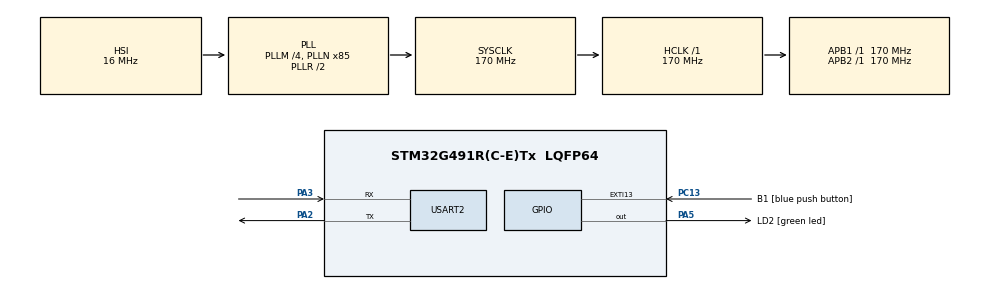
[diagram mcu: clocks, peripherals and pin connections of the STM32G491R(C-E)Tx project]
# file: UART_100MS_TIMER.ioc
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Mcu.Family=STM32G4
Mcu.Name=STM32G491R(C-E)Tx
Mcu.Package=LQFP64
NVIC.EXTI15_10_IRQn=true\:0\:0\:false\:false\:true\:true\:true\:true
NVIC.PriorityGroup=NVIC_PRIORITYGROUP_4
NVIC.TIM6_DAC_IRQn=true\:0\:0\:false\:false\:true\:true\:true\:true
NVIC.USART2_IRQn=true\:0\:0\:false\:false\:true\:true\:true\:true
PA13.GPIO_Label=T_SWDIO
PA13.Signal=SYS_JTMS-SWDIO
PA14.GPIO_Label=T_SWCLK
PA14.Signal=SYS_JTCK-SWCLK
PA2.Mode=Asynchronous
PA2.Signal=USART2_TX
PA3.Mode=Asynchronous
PA3.Signal=USART2_RX
PA5.GPIO_Label=LD2 [green led]
PA5.Signal=GPIO_Output
PB3.GPIO_Label=T_SWO
PB3.Signal=SYS_JTDO-SWO
PC13.GPIO_Label=B1 [blue push button]
PC13.Signal=GPXTI13
PC14-OSC32_IN.GPIO_Label=RCC_OSC32_IN
PC14-OSC32_IN.Signal=RCC_OSC32_IN
PC15-OSC32_OUT.GPIO_Label=RCC_OSC32_OUT
PC15-OSC32_OUT.Signal=RCC_OSC32_OUT
PF0-OSC_IN.GPIO_Label=RCC_OSC_IN
PF0-OSC_IN.Mode=HSE-External-Oscillator
PF0-OSC_IN.Signal=RCC_OSC_IN
PF1-OSC_OUT.GPIO_Label=RCC_OSC_OUT
PF1-OSC_OUT.Mode=HSE-External-Oscillator
PF1-OSC_OUT.Signal=RCC_OSC_OUT
ProjectManager.HeapSize=0x200
ProjectManager.StackSize=0x400
ProjectManager.TargetToolchain=STM32CubeIDE
RCC.ADC12Freq_Value=170000000
RCC.ADC345Freq_Value=170000000
RCC.AHBFreq_Value=170000000
RCC.APB1Freq_Value=170000000
RCC.APB1TimFreq_Value=170000000
RCC.APB2Freq_Value=170000000
RCC.APB2TimFreq_Value=170000000
RCC.CortexFreq_Value=170000000
RCC.EXTERNAL_CLOCK_VALUE=12288000
RCC.HCLKFreq_Value=170000000
RCC.HSE_VALUE=24000000
RCC.HSI48_VALUE=48000000
RCC.HSI_VALUE=16000000
RCC.LSE_VALUE=32768
RCC.PLLM=RCC_PLLM_DIV4
RCC.PLLN=85
RCC.RTCClockSelection=RCC_RTCCLKSOURCE_LSE
RCC.SYSCLKFreq_VALUE=170000000
RCC.SYSCLKSource=RCC_SYSCLKSOURCE_PLLCLK
RCC.USBFreq_Value=48000000
RCC.VCOOutputFreq_Value=340000000
TIM6.PeriodNoDither=1000-1
TIM6.Prescaler=17000-1
USART2.VirtualMode-Asynchronous=VM_ASYNC
VP_SYS_VS_DBSignals.Mode=DisableDeadBatterySignals
VP_TIM6_VS_ClockSourceINT.Mode=Enable_Timer
board=NUCLEO-G491RE

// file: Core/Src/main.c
/* USER CODE BEGIN Header */
/**
  ******************************************************************************
  * @file           : main.c
  * @brief          : Main program body
  ******************************************************************************
  */
/* USER CODE END Header */

#include "main.h"

TIM_HandleTypeDef htim6;
UART_HandleTypeDef huart2;

/* USER CODE BEGIN PV */
volatile uint8_t uart_send_flag = 0;
uint8_t TX_Buffer[] = "Hello World\r\n";
/* USER CODE END PV */

void SystemClock_Config(void);
static void MX_GPIO_Init(void);
static void MX_TIM6_Init(void);
static void MX_USART2_UART_Init(void);

int main(void)
{
  HAL_Init();
  SystemClock_Config();

  MX_GPIO_Init();
  MX_TIM6_Init();
  MX_USART2_UART_Init();

  /* Start TIM6 interrupt (100 ms hardware timer) */
  HAL_TIM_Base_Start_IT(&htim6);

  while (1)
  {
    /* Handle UART transmission outside interrupt */
    if (uart_send_flag)
    {
      uart_send_flag = 0;

      HAL_UART_Transmit(&huart2,
                        TX_Buffer,
                        sizeof(TX_Buffer) - 1,
                        HAL_MAX_DELAY);
    }
  }
}

/* ================= TIMER 6 INIT ================= */

static void MX_TIM6_Init(void)
{
  TIM_MasterConfigTypeDef sMasterConfig = {0};

  htim6.Instance = TIM6;
  htim6.Init.Prescaler = 17000 - 1;   // 170 MHz / 17000 = 10 kHz
  htim6.Init.CounterMode = TIM_COUNTERMODE_UP;
  htim6.Init.Period = 1000 - 1;       // 1000 ticks = 100 ms
  htim6.Init.AutoReloadPreload = TIM_AUTORELOAD_PRELOAD_DISABLE;

  if (HAL_TIM_Base_Init(&htim6) != HAL_OK)
  {
    Error_Handler();
  }

  sMasterConfig.MasterOutputTrigger = TIM_TRGO_RESET;
  sMasterConfig.MasterSlaveMode = TIM_MASTERSLAVEMODE_DISABLE;

  if (HAL_TIMEx_MasterConfigSynchronization(&htim6, &sMasterConfig) != HAL_OK)
  {
    Error_Handler();
  }
}

/* ================= UART INIT ================= */

static void MX_USART2_UART_Init(void)
{
  huart2.Instance = USART2;
  huart2.Init.BaudRate = 115200;
  huart2.Init.WordLength = UART_WORDLENGTH_8B;
  huart2.Init.StopBits = UART_STOPBITS_1;
  huart2.Init.Parity = UART_PARITY_NONE;
  huart2.Init.Mode = UART_MODE_TX_RX;
  huart2.Init.HwFlowCtl = UART_HWCONTROL_NONE;
  huart2.Init.OverSampling = UART_OVERSAMPLING_16;
  huart2.Init.OneBitSampling = UART_ONE_BIT_SAMPLE_DISABLE;
  huart2.Init.ClockPrescaler = UART_PRESCALER_DIV1;
  huart2.AdvancedInit.AdvFeatureInit = UART_ADVFEATURE_NO_INIT;

  if (HAL_UART_Init(&huart2) != HAL_OK)
  {
    Error_Handler();
  }
}

/* ================= GPIO INIT ================= */

static void MX_GPIO_Init(void)
{
  GPIO_InitTypeDef GPIO_InitStruct = {0};

  __HAL_RCC_GPIOC_CLK_ENABLE();
  __HAL_RCC_GPIOF_CLK_ENABLE();
  __HAL_RCC_GPIOA_CLK_ENABLE();
  __HAL_RCC_GPIOB_CLK_ENABLE();

  HAL_GPIO_WritePin(LD2_GPIO_Port, LD2_Pin, GPIO_PIN_RESET);

  GPIO_InitStruct.Pin = LD2_Pin;
  GPIO_InitStruct.Mode = GPIO_MODE_OUTPUT_PP;
  GPIO_InitStruct.Pull = GPIO_NOPULL;
  GPIO_InitStruct.Speed = GPIO_SPEED_FREQ_LOW;
  HAL_GPIO_Init(LD2_GPIO_Port, &GPIO_InitStruct);
}

/* ================= TIMER CALLBACK ================= */

void HAL_TIM_PeriodElapsedCallback(TIM_HandleTypeDef *htim)
{
  if (htim->Instance == TIM6)
  {
    uart_send_flag = 1;   // Set flag only (fast, safe ISR)
  }
}

/* ================= CLOCK CONFIG ================= */

void SystemClock_Config(void)
{
  RCC_OscInitTypeDef RCC_OscInitStruct = {0};
  RCC_ClkInitTypeDef RCC_ClkInitStruct = {0};

  HAL_PWREx_ControlVoltageScaling(PWR_REGULATOR_VOLTAGE_SCALE1_BOOST);

  RCC_OscInitStruct.OscillatorType = RCC_OSCILLATORTYPE_HSI;
  RCC_OscInitStruct.HSIState = RCC_HSI_ON;
  RCC_OscInitStruct.HSICalibrationValue = RCC_HSICALIBRATION_DEFAULT;
  RCC_OscInitStruct.PLL.PLLState = RCC_PLL_ON;
  RCC_OscInitStruct.PLL.PLLSource = RCC_PLLSOURCE_HSI;
  RCC_OscInitStruct.PLL.PLLM = RCC_PLLM_DIV4;
  RCC_OscInitStruct.PLL.PLLN = 85;
  RCC_OscInitStruct.PLL.PLLP = RCC_PLLP_DIV2;
  RCC_OscInitStruct.PLL.PLLQ = RCC_PLLQ_DIV2;
  RCC_OscInitStruct.PLL.PLLR = RCC_PLLR_DIV2;

  if (HAL_RCC_OscConfig(&RCC_OscInitStruct) != HAL_OK)
  {
    Error_Handler();
  }

  RCC_ClkInitStruct.ClockType =
      RCC_CLOCKTYPE_HCLK |
      RCC_CLOCKTYPE_SYSCLK |
      RCC_CLOCKTYPE_PCLK1 |
      RCC_CLOCKTYPE_PCLK2;

  RCC_ClkInitStruct.SYSCLKSource = RCC_SYSCLKSOURCE_PLLCLK;
  RCC_ClkInitStruct.AHBCLKDivider = RCC_SYSCLK_DIV1;
  RCC_ClkInitStruct.APB1CLKDivider = RCC_HCLK_DIV1;
  RCC_ClkInitStruct.APB2CLKDivider = RCC_HCLK_DIV1;

  if (HAL_RCC_ClockConfig(&RCC_ClkInitStruct, FLASH_LATENCY_4) != HAL_OK)
  {
    Error_Handler();
  }
}

/* ================= ERROR HANDLER ================= */

void Error_Handler(void)
{
  __disable_irq();
  while (1) {}
}
